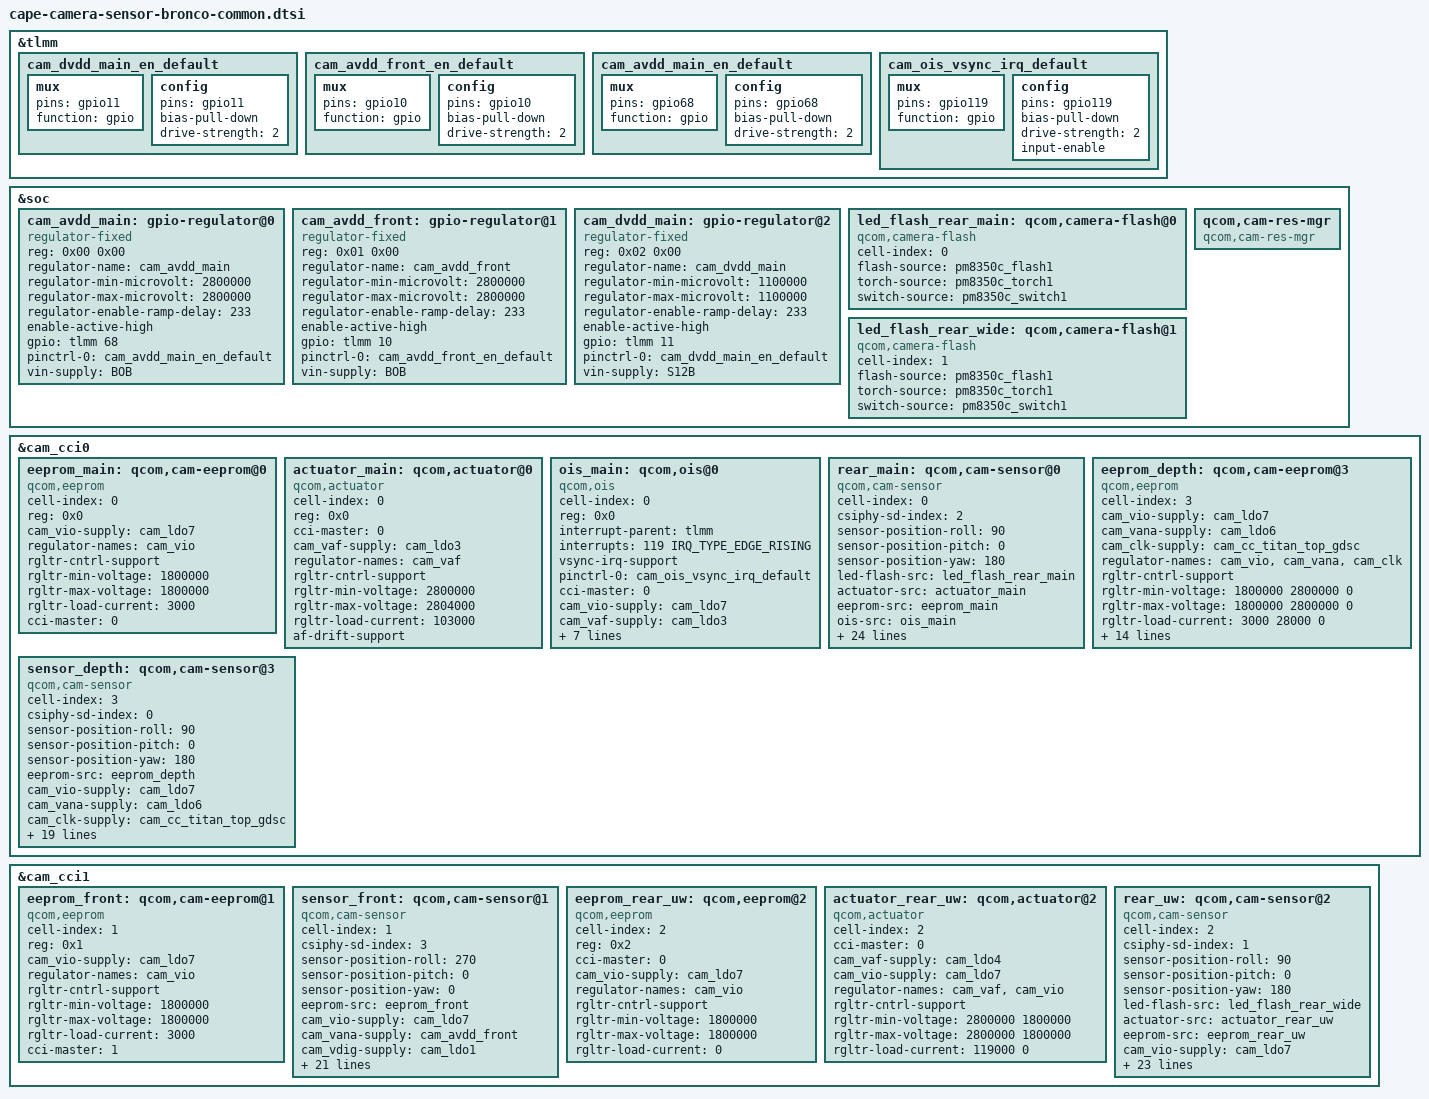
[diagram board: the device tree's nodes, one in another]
/*
   This base is original from "cape-camera-sensor-mtp.dtsi"
*/
#include <dt-bindings/clock/qcom,camcc-waipio.h>
#include <dt-bindings/msm-camera.h>

&tlmm {
	cam_dvdd_main_en_default: cam_dvdd_main_en_default {
		mux {
			pins = "gpio11";
			function = "gpio";
		};

		config {
			pins = "gpio11";
			bias-pull-down; /* PULL DOWN */
			drive-strength = <2>; /* 2 MA */
		};
	};

	cam_avdd_front_en_default: cam_avdd_front_en_default {
		mux {
			pins = "gpio10";
			function = "gpio";
		};

		config {
			pins = "gpio10";
			bias-pull-down; /* PULL DOWN */
			drive-strength = <2>; /* 2 MA */
		};
	};

	cam_avdd_main_en_default: cam_avdd_main_en_default {
		mux {
			pins = "gpio68";
			function = "gpio";
		};

		config {
			pins = "gpio68";
			bias-pull-down; /* PULL DOWN */
			drive-strength = <2>; /* 2 MA */
		};
	};

	cam_ois_vsync_irq_default: cam_ois_vsync_irq_default {
		mux {
			pins = "gpio119";
			function = "gpio";
		};
		config {
			pins = "gpio119";
			bias-pull-down; /* PULL UP */
			drive-strength = <2>;
			input-enable;
		};
	};
};

&soc {
	cam_avdd_main: gpio-regulator@0 {
		compatible = "regulator-fixed";
		reg = <0x00 0x00>;
		regulator-name = "cam_avdd_main";
		regulator-min-microvolt = <2800000>;
		regulator-max-microvolt = <2800000>;
		regulator-enable-ramp-delay = <233>;
		enable-active-high;
		gpio = <&tlmm 68 0>;
		pinctrl-names = "default";
		pinctrl-0 = <&cam_avdd_main_en_default>;
		vin-supply = <&BOB>;
	};

	cam_avdd_front: gpio-regulator@1 {
		compatible = "regulator-fixed";
		reg = <0x01 0x00>;
		regulator-name = "cam_avdd_front";
		regulator-min-microvolt = <2800000>;
		regulator-max-microvolt = <2800000>;
		regulator-enable-ramp-delay = <233>;
		enable-active-high;
		gpio = <&tlmm 10 0>;
		pinctrl-names = "default";
		pinctrl-0 = <&cam_avdd_front_en_default>;
		vin-supply = <&BOB>;
	};

	cam_dvdd_main: gpio-regulator@2 {
		compatible = "regulator-fixed";
		reg = <0x02 0x00>;
		regulator-name = "cam_dvdd_main";
		regulator-min-microvolt = <1100000>;
		regulator-max-microvolt = <1100000>;
		regulator-enable-ramp-delay = <233>;
		enable-active-high;
		gpio = <&tlmm 11 0>;
		pinctrl-names = "default";
		pinctrl-0 = <&cam_dvdd_main_en_default>;
		vin-supply = <&S12B>;
	};

	led_flash_rear_main: qcom,camera-flash@0 {
		cell-index = <0>;
		compatible = "qcom,camera-flash";
		flash-source = <&pm8350c_flash1>;
		torch-source = <&pm8350c_torch1>;
		switch-source = <&pm8350c_switch1>;
		status = "ok";
	};

	led_flash_rear_wide: qcom,camera-flash@1 {
		cell-index = <1>;
		compatible = "qcom,camera-flash";
		flash-source = <&pm8350c_flash1>;
		torch-source = <&pm8350c_torch1>;
		switch-source = <&pm8350c_switch1>;
		status = "ok";
	};

	qcom,cam-res-mgr {
		compatible = "qcom,cam-res-mgr";
		status = "ok";
	};
};

&cam_cci0 {
	eeprom_main: qcom,cam-eeprom@0 {
		cell-index = <0>;
		reg = <0x0>;
		compatible = "qcom,eeprom";
		cam_vio-supply = <&cam_ldo7>;
		regulator-names = "cam_vio";
		rgltr-cntrl-support;
		rgltr-min-voltage = <1800000>;
		rgltr-max-voltage = <1800000>;
		rgltr-load-current = <3000>;
		cci-master = <0>;
		status = "ok";
	};

	actuator_main: qcom,actuator@0 {
		cell-index = <0>;
		reg = <0x0>;
		compatible = "qcom,actuator";
		cci-master = <0>;
		cam_vaf-supply = <&cam_ldo3>;
		regulator-names = "cam_vaf";
		rgltr-cntrl-support;
		rgltr-min-voltage = <2800000>;
		rgltr-max-voltage = <2804000>;
		rgltr-load-current = <103000>;
		af-drift-support;
		status = "ok";
	};

	ois_main: qcom,ois@0 {
		cell-index = <0>;
		reg = <0x0>;
		compatible = "qcom,ois";
		interrupt-parent = <&tlmm>;
		interrupts = <119 IRQ_TYPE_EDGE_RISING>;
		vsync-irq-support;
		pinctrl-names = "default";
		pinctrl-0 = <&cam_ois_vsync_irq_default>;
		cci-master = <0>;
		cam_vio-supply       = <&cam_ldo7>;
		cam_vaf-supply       = <&cam_ldo3>;
		cam_v_custom1-supply = <&cam_ldo5>;
		regulator-names      = "cam_vio", "cam_vaf", "cam_v_custom1";
		rgltr-cntrl-support;
		rgltr-min-voltage  = <1800000 2800000 2800000>;
		rgltr-max-voltage  = <1800000 2804000 2800000>;
		rgltr-load-current = <14000    119000  119000>;
		status = "ok";
	};

	rear_main: qcom,cam-sensor@0 {
		cell-index = <0>;
		compatible = "qcom,cam-sensor";
		csiphy-sd-index = <2>;
		sensor-position-roll = <90>;
		sensor-position-pitch = <0>;
		sensor-position-yaw = <180>;
		led-flash-src = <&led_flash_rear_main>;
		actuator-src  = <&actuator_main>;
		eeprom-src    = <&eeprom_main>;
		ois-src       = <&ois_main>;
		cam_vio-supply  = <&cam_ldo7>;
		cam_vdig-supply = <&cam_dvdd_main>;
		cam_clk-supply  = <&cam_cc_titan_top_gdsc>;
		cam_vana-supply = <&cam_avdd_main>;
		regulator-names = "cam_vio", "cam_vdig", "cam_clk", "cam_vana";
		rgltr-cntrl-support;
		rgltr-min-voltage  = <1800000 1100000 0 2800000>;
		rgltr-max-voltage  = <1800000 1100000 0 2800000>;
		rgltr-load-current = <155000  680000  0 50000>;
		gpio-no-mux = <0>;
		pinctrl-names = "cam_default", "cam_suspend";
		pinctrl-0 = <&cam_sensor_mclk2_active	&cam_sensor_active_rst2>;
		pinctrl-1 = <&cam_sensor_mclk2_suspend	&cam_sensor_suspend_rst2>;
		gpios = <&tlmm 102 0>, <&tlmm 117 0>;
		gpio-reset = <1>;
		gpio-req-tbl-num   = <0 1>;
		gpio-req-tbl-flags = <1 0>;
		gpio-req-tbl-label = "CAMIF_MCLK2",	"CAM_RESET2";
		cci-master = <0>;
		clocks = <&clock_camcc CAM_CC_MCLK2_CLK>;
		clock-names = "cam_clk";
		clock-cntl-level = "nominal";
		clock-rates = <24000000>;
		status = "ok";
	};

	eeprom_depth: qcom,cam-eeprom@3 {
		cell-index = <3>;
		compatible = "qcom,eeprom";
		cam_vio-supply  = <&cam_ldo7>;
		cam_vana-supply = <&cam_ldo6>;
		cam_clk-supply  = <&cam_cc_titan_top_gdsc>;
		regulator-names = "cam_vio", "cam_vana","cam_clk";
		rgltr-cntrl-support;
		rgltr-min-voltage  = <1800000 2800000 0>;
		rgltr-max-voltage  = <1800000 2800000 0>;
		rgltr-load-current = <3000    28000   0>;
		gpio-no-mux = <0>;
		pinctrl-names = "cam_default", "cam_suspend";
		pinctrl-0 = <&cam_sensor_mclk1_active	&cam_sensor_active_rst1>;
		pinctrl-1 = <&cam_sensor_mclk1_suspend	&cam_sensor_suspend_rst1>;
		gpios = <&tlmm 101 0>, <&tlmm 24 0>;
		gpio-reset = <1>;
		gpio-req-tbl-num   = <0 1>;
		gpio-req-tbl-flags = <1 0>;
		gpio-req-tbl-label = "CAMIF_MCLK1",	"CAM_RESET1";
		cci-master = <1>;
		clocks = <&clock_camcc CAM_CC_MCLK1_CLK>;
		clock-names      = "cam_clk";
		clock-cntl-level = "nominal";
		clock-rates      = <24000000>;
		status = "ok";
    };

	sensor_depth: qcom,cam-sensor@3 {
		cell-index = <3>;
		compatible = "qcom,cam-sensor";
		csiphy-sd-index = <0>;
		sensor-position-roll  = <90>;
		sensor-position-pitch = <0>;
		sensor-position-yaw   = <180>;
		eeprom-src = <&eeprom_depth>;
		cam_vio-supply  = <&cam_ldo7>;
		cam_vana-supply = <&cam_ldo6>;
		cam_clk-supply  = <&cam_cc_titan_top_gdsc>;
		regulator-names = "cam_vio", "cam_vana","cam_clk";
		rgltr-cntrl-support;
		rgltr-min-voltage  = <1800000 2800000 0>;
		rgltr-max-voltage  = <1800000 2800000 0>;
		rgltr-load-current = <3000    28000   0>;
		gpio-no-mux = <0>;
		pinctrl-names = "cam_default", "cam_suspend";
		pinctrl-0 = <&cam_sensor_mclk1_active	&cam_sensor_active_rst1>;
		pinctrl-1 = <&cam_sensor_mclk1_suspend	&cam_sensor_suspend_rst1>;
		gpios = <&tlmm 101 0>, <&tlmm 24 0>;
		gpio-reset = <1>;
		gpio-req-tbl-num   = <0 1>;
		gpio-req-tbl-flags = <1 0>;
		gpio-req-tbl-label = "CAMIF_MCLK1",	"CAM_RESET1";
		cci-master = <1>;
		clocks = <&clock_camcc CAM_CC_MCLK1_CLK>;
		clock-names      = "cam_clk";
		clock-cntl-level = "nominal";
		clock-rates      = <24000000>;
		status = "ok";
	};
};

&cam_cci1 {
	eeprom_front: qcom,cam-eeprom@1 {
		cell-index = <1>;
		reg = <0x1>;
		compatible = "qcom,eeprom";
		cam_vio-supply = <&cam_ldo7>;
		regulator-names = "cam_vio";
		rgltr-cntrl-support;
		rgltr-min-voltage = <1800000>;
		rgltr-max-voltage = <1800000>;
		rgltr-load-current = <3000>;
		cci-master = <1>;
		status = "ok";
	};

	sensor_front: qcom,cam-sensor@1 {
		cell-index = <1>;
		compatible = "qcom,cam-sensor";
		csiphy-sd-index = <3>;
		sensor-position-roll = <270>;
		sensor-position-pitch = <0>;
		sensor-position-yaw = <0>;
		eeprom-src   = <&eeprom_front>;
		cam_vio-supply  = <&cam_ldo7>;
		cam_vana-supply = <&cam_avdd_front>;
		cam_vdig-supply = <&cam_ldo1>;
		cam_clk-supply  = <&cam_cc_titan_top_gdsc>;
		regulator-names = "cam_vio", "cam_vana", "cam_vdig", "cam_clk";
		rgltr-cntrl-support;
		rgltr-min-voltage  = <1800000 2800000 1100000 0>;
		rgltr-max-voltage  = <1800000 2800000 1100000 0>;
		rgltr-load-current = <300    39000  93000  0>;
		gpio-no-mux = <0>;
		pinctrl-names = "cam_default", "cam_suspend";
		pinctrl-0 = <&cam_sensor_mclk4_active	&cam_sensor_active_rst6>;
		pinctrl-1 = <&cam_sensor_mclk4_suspend	&cam_sensor_suspend_rst6>;
		gpios = <&tlmm 104 0>, <&tlmm 108 0>;
		gpio-reset = <1>;
		gpio-req-tbl-num = <0 1>;
		gpio-req-tbl-flags = <1 0>;
		gpio-req-tbl-label = "CAMIF_MCLK4", "CAM_RESET4";
		cci-master = <1>;
		clocks = <&clock_camcc CAM_CC_MCLK4_CLK>;
		clock-names = "cam_clk";
		clock-cntl-level = "nominal";
		clock-rates = <24000000>;
		status = "ok";
	};

	eeprom_rear_uw: qcom,eeprom@2 {
		cell-index = <2>;
		reg = <0x2>;
		compatible = "qcom,eeprom";
		cci-master = <0>;
		cam_vio-supply = <&cam_ldo7>;
		regulator-names = "cam_vio";
		rgltr-cntrl-support;
		rgltr-min-voltage = <1800000>;
		rgltr-max-voltage = <1800000>;
		rgltr-load-current = <0>;
	};

	actuator_rear_uw: qcom,actuator@2 {
		cell-index = <2>;
		compatible = "qcom,actuator";
		cci-master = <0>;
		cam_vaf-supply = <&cam_ldo4>;
		cam_vio-supply = <&cam_ldo7>;
		regulator-names = "cam_vaf", "cam_vio";
		rgltr-cntrl-support;
		rgltr-min-voltage = <2800000 1800000>;
		rgltr-max-voltage = <2800000 1800000>;
		rgltr-load-current = <119000 0>;
		status = "ok";
	};

	rear_uw: qcom,cam-sensor@2 {
		cell-index = <2>;
		compatible = "qcom,cam-sensor";
		csiphy-sd-index = <1>;
		sensor-position-roll = <90>;
		sensor-position-pitch = <0>;
		sensor-position-yaw = <180>;
		led-flash-src = <&led_flash_rear_wide>;
		actuator-src  = <&actuator_rear_uw>;
		eeprom-src    = <&eeprom_rear_uw>;
		cam_vio-supply  = <&cam_ldo7>;
		cam_clk-supply  = <&cam_cc_titan_top_gdsc>;
		cam_vana-supply = <&cam_ldo6>;
		cam_vdig-supply = <&cam_ldo2>;
		regulator-names = "cam_vio", "cam_vana", "cam_vdig", "cam_clk";
		rgltr-cntrl-support;
		rgltr-min-voltage = <1800000 2800000 1100000 0>;
		rgltr-max-voltage = <1800000 2800000 1100000 0>;
		rgltr-load-current = <7000   132000  405000  0>;
		gpio-no-mux = <0>;
		pinctrl-names = "cam_default", "cam_suspend";
		pinctrl-0     = <&cam_sensor_mclk3_active	&cam_sensor_active_rst3>;
		pinctrl-1     = <&cam_sensor_mclk3_suspend	&cam_sensor_suspend_rst3>;
		gpios = <&tlmm 103 0>,	<&tlmm 120 0>;
		gpio-reset = <1>;
		gpio-req-tbl-num = <0 1>;
		gpio-req-tbl-flags = <1 0>;
		gpio-req-tbl-label = "CAMIF_MCLK3",	"CAM_RESET3";
		cci-master = <0>;
		clocks = <&clock_camcc CAM_CC_MCLK3_CLK>;
		clock-names = "cam_clk";
		clock-cntl-level = "nominal";
		clock-rates = <24000000>;
		status = "ok";
	};
};
